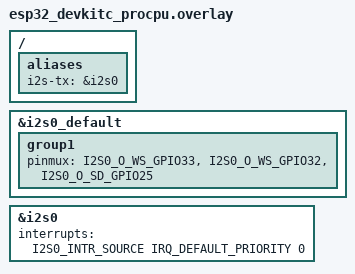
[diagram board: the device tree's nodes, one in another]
/*
 * Copyright (c) 2025 Espressif Systems (Shanghai) Co., Ltd.
 *
 * SPDX-License-Identifier: Apache-2.0
 */

/ {
	aliases {
		i2s-tx = &i2s0;
	};
};

&i2s0_default {
	group1 {
		pinmux = <I2S0_O_WS_GPIO33>,
			 <I2S0_O_WS_GPIO32>,
			 <I2S0_O_SD_GPIO25>;
	};
};

&i2s0 {
	status = "okay";

	interrupts = <I2S0_INTR_SOURCE IRQ_DEFAULT_PRIORITY 0>;
	interrupt-names = "tx";
};
